# DA14682 register map
Vendor: Dialog; Series: DA14682; File version: 1.2
CPU: CM0 r1p0, little endian, MPU, FPU, 3 interrupt priority bits
Registers are 16-bit, read-write, reset 0x0 unless marked. A register's access mark holds for its fields unless they carry their own. Offsets are from the block's base; [hi:lo] are bit positions; {n}, {i} and the like mark numbered series; 'fields as' and 'values as' point back to an identical list.

## COEX — COEX registers
Base 0x50002F00
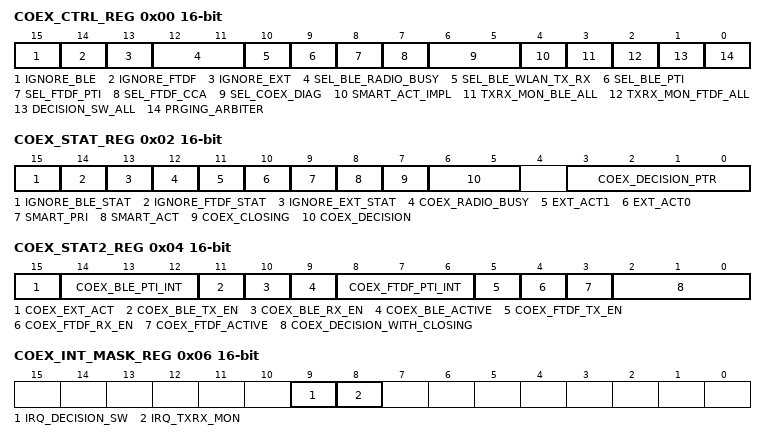
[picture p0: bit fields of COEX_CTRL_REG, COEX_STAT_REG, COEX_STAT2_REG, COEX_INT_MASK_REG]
0x00 COEX_CTRL_REG — COEX Control Register
  [15] IGNORE_BLE — If set to "1" then all BLE requests are ignored by masking the internal "ble_active" signal. Refer also to IGNORE_BLE_STAT.
  [14] IGNORE_FTDF — If set to "1" then all FTDF requests are ignored by masking the internal "ftdf_active" signal. Refer also to IGNORE_FTDF_STAT.
  [13] IGNORE_EXT — If set to "1" then all EXT requests are ignored by masking the internal "ext_act" signal ("ext_act" is the logical OR of "ext_act0" and "ext_act1"). Refer also to IGNORE_EXT_STAT.
  [12:11] SEL_BLE_RADIO_BUSY — Select the logic driving the BLE core input "ble.radio_busy": 0: (decision==BLE) AND rfcu.radio_busy. 1: Hold to "0". 2: (decision==FTDF) OR (decision==EXT) OR rfcu.radio_busy. 3: (decision==FTDF) OR (decision==EXT). Selection "0" is the default, while selection "2" is the recommended value if the BLE SW supports it.
  [10] SEL_BLE_WLAN_TX_RX — If set to "1" then the COEX block will drive the WLAN_TX and WLAN_RX inputs of the BLE core. Otherwise both BLE inputs will be forced to "0".
  [9] SEL_BLE_PTI — It controls the source of the BLE PTI value that the COEX Arbiter will use. If "0" then use the COEX_BLE_PTI_REG. If "1" then use the PTI value provided by the BLE core.
  [8] SEL_FTDF_PTI — It controls the source of the FTDF PTI value that the COEX Arbiter will use. If "0" then use the COEX_FTDF_PTI_REG. If "1" then use the PTI value provided by the FTDF core.
  [7] SEL_FTDF_CCA — If set to "1" and the COEX decision is different than "FTDF", then the CCA_STAT signal going to FTDF (generated from the radio) will be forced to "1"; otherwise the FTDF.CCA_STAT will be driven with the signal generated from the radio. Recommended value for SEL_FTDF_CCA is "1".
  [6:5] SEL_COEX_DIAG — The COEX block can provide internal diagnostic signals by overwriting the BLE diagnostic bus, which is forwarded to GPIO multiplexing. There is no need to program the BLE registers, but only this field and the GPIO PID fields. 0: No COEX diagnostics, only BLE. 1: BLE_DIAG[4:3]=decision[1:0]; BLE_DIAG[5]=closing. 2: BLE_DIAG[4:3]=decision[1:0]; BLE_DIAG[5]=closing; BLE_DIAG[6]=OR( ftdf/ble2coex_tx/rx_en ) 3: BLE_DIAG[2]=closing OR radio_busy; BLE_DIAG[6:3]=decision_ptr[3:0]; BLE_DIAG[7]=0.
  [4] SMART_ACT_IMPL — Controls the behavior of the SMART_ACT (and SMART_PRI as a consequence). If SMART_ACT_IMPL="0" then if any BLE or FTDF MAC request is active then SMART_ACT will be asserted. SMART_ACT will actually be the logical OR of "ble_active" and "ftdf_active" internal signals. SMART_ACT will be asserted regardless the decision of the Arbiter to allow or disallow the access to the on-chip radio from the active MAC(s). if SMART_ACT_IMPL="1" then if the Arbiter's decision is to allow EXTernal MAC, then keep SMART_ACT to "0", otherwise follow the implementation of SMART_ACT_IMPL="0".
  [3] TXRX_MON_BLE_ALL — It controls the behavior of the Monitoring bitfields COEX_INT_STAT_REG[ *TXRX_MON* ] If "0" then update the Monitoring bitfields with BLE Rx/Tx that has been masked. If "1" then update for every BLE Rx/Tx, either masked or not.
  [2] TXRX_MON_FTDF_ALL — It controls the behavior of the Monitoring bitfields COEX_INT_STAT_REG[ *TXRX_MON* ] If "0" then update the Monitoring bitfields with FTDF Rx/Tx that has been masked. If "1" then update for every FTDF Rx/Tx, either masked or not.
  [1] DECISION_SW_ALL — Refer to COEX_INT_STAT_REG[ IRQ_DECISION_SW ] bitfield description.
  [0] PRGING_ARBITER — If set to "1" then the current transaction (Tx or Rx) will complete normally and after that no further decision will be taken by the arbiter. Will be set to "1" automatically by the HW as soon as a write operation will be detected to the COEX_PRIx_REG registers. As soon as the update on the priorities will be completed, the SW should clear this bit. The SW can set or clear this bit. Note: Depending on the relationship between the PCLK and COEX_CLK periods a write operation to this bitfield may be effective in more than one PCLK clock cycles.
0x02 COEX_STAT_REG — COEX Status Register
  [15] IGNORE_BLE_STAT ro — This signal is constantly "1" on FTDF-only chips. If set to "1" then all BLE requests are ignored by masking immediately the request signal from the BLE. In more detail, the internal signal "ble_active" is the logical AND of this bitfield and the "ble.event_in_process".
  [14] IGNORE_FTDF_STAT ro — This signal is constantly "1" on BLE-only chips. If set to "1" then all FTDF requests are ignored by masking immediately the request signal from the FTDF. In more detail, the internal signal "ftdf_active" is the logical AND of this bitfield and the "ftdf.phy_en".
  [13] IGNORE_EXT_STAT ro — If set to "1" then all EXT requests are ignored by masking immediately the request signal from the external MAC. In more detail, the internal signal "ext_active" is the logical AND of this bitfield and the "ext_act".
  [12] COEX_RADIO_BUSY ro — Current state of RADIO_BUSY signal generated from RFCU, which is the logical OR among all Radio DCFs. Note that the arbiter will process this value with one COEX clock cycle delay.
  [11] EXT_ACT1 ro — Current state of the pin.
  [10] EXT_ACT0 ro — Current state of the pin.
  [9] SMART_PRI ro — Current state of the pin.
  [8] SMART_ACT ro — Current state of the pin.
  [7] COEX_CLOSING ro — Provides the value of the "CLOSING" substate.
  [6:5] COEX_DECISION ro — Decision values: 0: Decision is NONE. 1: Decision is BLE. 2: Decision is FTDF. 3: Decision is EXT. Note: If "0" (i.e. decision is NONE) then no MAC will have access to the on-chip radio. As a consequence, the SMART_PRI signal will stay low, since no on-chip (SMART) MAC will have priority. Note: While in programming mode, the COEX_PRIx_REGs are considered as invalid, which means that no new decision can be taken. Note: The decision NONE will be held as long as there is no "*_active" internal signal from BLE, FTDF or EXT. Also, if in programming state and the last transaction has been finished, then the decision will be held also to NONE.
  [3:0] COEX_DECISION_PTR ro — Provides the number "x" of the COEX_PRIx_REG that win the last arbitration cycle. If "0" then it is a null pointer, pointing to no COEX_PRIx_REG.
0x04 COEX_STAT2_REG — COEX Status 2 Register
  [15] COEX_EXT_ACT ro — The internal EXT_ACT used for the decision taking.
  [14:12] COEX_BLE_PTI_INT ro — The BLE PTI value that is used for decision taking.
  [11] COEX_BLE_TX_EN ro — The current value of BLE TX_EN.
  [10] COEX_BLE_RX_EN ro — The current value of BLE RX_EN.
  [9] COEX_BLE_ACTIVE ro — The internal BLE_ACTIVE signal used for decision taking.
  [8:6] COEX_FTDF_PTI_INT ro — The FTDF PTI value that is used for decision taking. Value depends on COEX_CTRL_REG.SEL_FTDF_PTI.
  [5] COEX_FTDF_TX_EN ro — The current value of FTDF TX_EN.
  [4] COEX_FTDF_RX_EN ro — The current value of FTDF RX_EN.
  [3] COEX_FTDF_ACTIVE ro — The internal FTDF_ACTIVE signal used for the decision taking.
  [2:0] COEX_DECISION_WITH_CLOSING ro — DECISION (bits [1:0]) appended the CLOSING (bit [2]) state.
0x06 COEX_INT_MASK_REG — COEX Interrupt Mask Register
  [9] IRQ_DECISION_SW — If "1" then a "1" on COEX_INT_STAT_REG[IRQ_DECISION_SW] will generate an IRQ to CPU.
  [8] IRQ_TXRX_MON — If "1" then a "1" on COEX_INT_STAT_REG[IRQ_TXRX_MON] will generate an IRQ to CPU.
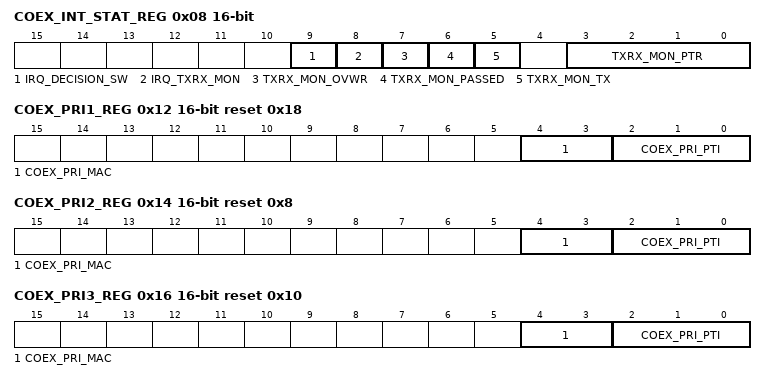
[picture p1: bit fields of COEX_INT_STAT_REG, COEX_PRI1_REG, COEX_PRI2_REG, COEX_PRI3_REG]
0x08 COEX_INT_STAT_REG — COEX Interrupt Status Register
  [9] IRQ_DECISION_SW ro — IRQ event when the DECISION switches to another value. If DECISION_SW_ALL=1, then it reports any change of DECISION value. If DECISION_SW_ALL=0, then it reports only the switches to another MAC, ignoring also the intermediate transitions to DECISION==NONE. For example the sequence FTDF-NONE-FTDF-NONE-BLE-NONE-BLE will report only the first switch from NONE to BLE. Note that after a Radio Power domain reset, the first transition of the DECISION to any non-NONE value will also trigger this event.
  [8] IRQ_TXRX_MON ro — Tx/Rx Monitor event pending. When this bitfield is set, then there is a valid entry at the bitfields TXRX_MON_PTR, TXRX_MON_TX, TXRX_MON_PASSED and TXRX_MON_OVWR.
  [7] TXRX_MON_OVWR ro — Tx/Rx Monitor entry Overwritten. if "1" then TXRX_MON_PTR loaded a new value without being cleared first by the software. Provides an indication that the software does not fetch the TXRX_MON_PTR fast enough.
  [6] TXRX_MON_PASSED ro — This bit indicates if the corresponding TXRX_MON_PTR pointer indicates a Tx/Rx that has been masked or not by the COEX block. If "0" then the Tx/Rx has been masked. If "1" then the Tx/Rx has not been masked. The bitfield is valid only when TXRX_MON_PTR is not zero.
  [5] TXRX_MON_TX ro — If "0" then the corresponding TXRX_MON_PTR corresponds to an Rx. If "1" then the corresponding TXRX_MON_PTR corresponds to an Tx. The bitfield is valid only when TXRX_MON_PTR is not zero.
  [3:0] TXRX_MON_PTR ro — Tx/Rx Monitor Pointer. If not zero then it provides a pointer to the Priority registers indicating the completion of an Tx or Rx (deassertion of TX_EN or RX_EN) that corresponds to this Priority register. Refer also to the COEX_CTRL_REG[ TXRX_MON_ALL ] control bit. If the PTI that corresponds to the deasserted TX_EN/RX_EN is not in the Priority Register list, then this event will be ignored and will not be reported by the TXRX Monitoring bitfields. Reading the register will clear the bitfield.
0x0A COEX_BLE_PTI_REG — COEX BLE PTI Control Register
  [2:0] COEX_BLE_PTI — This value specifies the PTI value that characterizes the next BLE transaction that will be initiated on the following "ble_active" positive edge. The value should remain constant during the high period of the "ble_active" signal.
0x0C COEX_FTDF_PTI_REG — COEX FTDF PTI Control Register
  [2:0] COEX_FTDF_PTI — This value specifies the PTI value that characterizes the next FTDF transaction that will be initiated on the following "ftdf_active" positive edge. The value should remain constant during the high period of the "ftdf_active" signal. Refer also to bitfield COEX_CTRL_REG.SEL_FTDF_PTI.
0x12 COEX_PRI1_REG reset 0x18 — COEX Priority Register
  [4:3] COEX_PRI_MAC — Specifies the MAC that has been assigned with the specific priority level. The MAC encoding follows the COEX_DECISION bitfield encoding.
  [2:0] COEX_PRI_PTI — The priority level specified by the name of this register will be applied to the packets coming from the MAC specified by the COEX_PRI_MAC bitfield and characterized with the PTI value specified by the COEX_PRI_PTI bitfield. The effective PTI value of the packets coming from BLE and FTDF is controlled by the register bitfields SEL_BLE_PTI and SEL_FTDF_PTI, while for the External MAC (EXT) the PTI is considered always as "0".
0x14 COEX_PRI2_REG reset 0x8 — COEX Priority Register
  [4:3] COEX_PRI_MAC — Refer to COEX_PRI1_REG.
  [2:0] COEX_PRI_PTI — Refer to COEX_PRI1_REG.
0x16 COEX_PRI3_REG reset 0x10 — COEX Priority Register
  fields as COEX_PRI2_REG
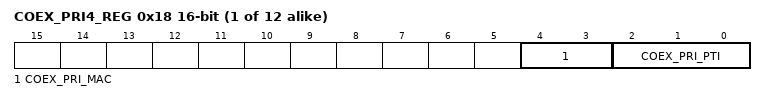
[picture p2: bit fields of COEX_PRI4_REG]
{0x10+2i} COEX_PRI{i}_REG (i=4..15) — COEX Priority Register
  fields as COEX_PRI2_REG
